VERSION ""

NS_ :

BS_:

BU_: Car1516_PDM

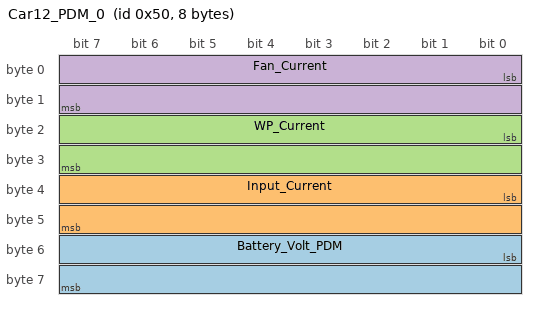
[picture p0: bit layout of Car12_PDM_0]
BO_ 80 Car12_PDM_0: 8 Car1516_PDM
 SG_ Battery_Volt_PDM : 48|16@1- (0.01,0) [0|0] "V" Vector__XXX
 SG_ Input_Current : 32|16@1- (0.01,0) [0|0] "A" Vector__XXX
 SG_ WP_Current : 16|16@1- (0.01,0) [0|0] "A" Vector__XXX
 SG_ Fan_Current : 0|16@1- (0.01,0) [0|0] "A" Vector__XXX
